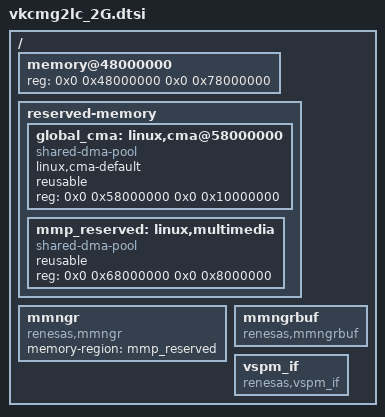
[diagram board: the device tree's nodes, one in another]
// SPDX-License-Identifier: GPL-2.0
/*
 * Device Tree Source for the Vekatech (VKRZG2LC Dual Cortex-A55)
 *
 * Copyright (C) 2026 Vekatech.
 */

#include "vkcmg2lc.dtsi"

/ {
	memory@48000000 {
		device_type = "memory";
		/* first 128MB is reserved for secure area. */
		reg = <0x0 0x48000000 0x0 0x78000000>;
	};

	reserved-memory {
		#address-cells = <2>;
		#size-cells = <2>;
		ranges;

		global_cma: linux,cma@58000000 {
			compatible = "shared-dma-pool";
			linux,cma-default;
			reusable;
			reg = <0x0 0x58000000 0x0 0x10000000>;
		};

		mmp_reserved: linux,multimedia {
			compatible = "shared-dma-pool";
			reusable;
			reg = <0x0 0x68000000 0x0 0x8000000>;
		};
	};

	mmngr {
		compatible = "renesas,mmngr";
		memory-region = <&mmp_reserved>;
	};

	mmngrbuf {
		compatible = "renesas,mmngrbuf";
	};

	vspm_if {
		compatible = "renesas,vspm_if";
	};
};

